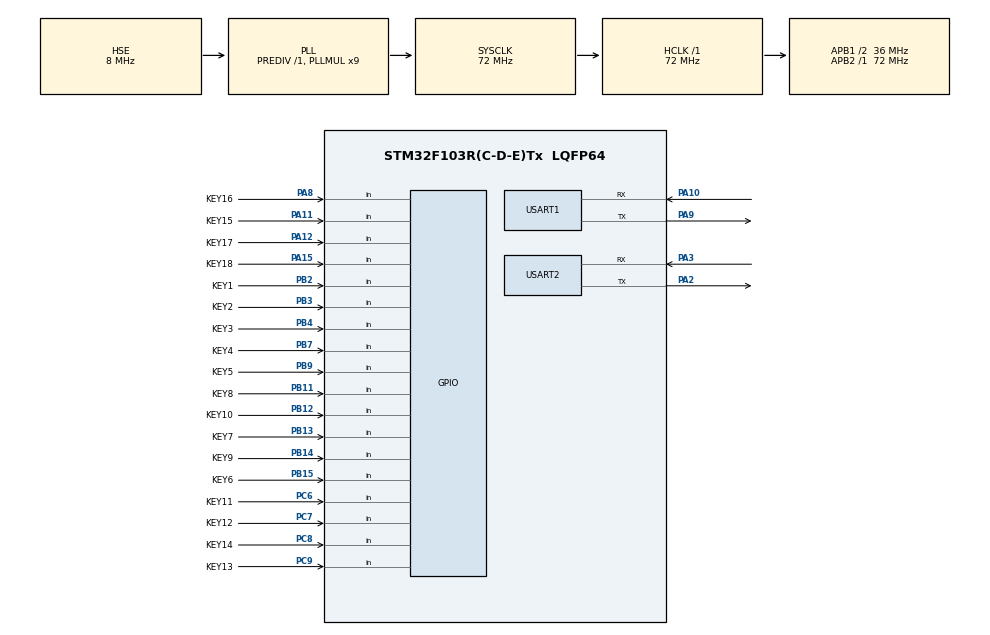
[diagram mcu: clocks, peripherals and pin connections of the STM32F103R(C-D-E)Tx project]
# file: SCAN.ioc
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Mcu.Family=STM32F1
Mcu.Name=STM32F103R(C-D-E)Tx
Mcu.Package=LQFP64
NVIC.PriorityGroup=NVIC_PRIORITYGROUP_4
NVIC.USART1_IRQn=true\:0\:0\:false\:false\:true
NVIC.USART2_IRQn=true\:0\:0\:false\:false\:true
PA10.Mode=Asynchronous
PA10.Signal=USART1_RX
PA11.GPIO_Label=KEY15
PA11.Signal=GPIO_Input
PA12.GPIO_Label=KEY17
PA12.Signal=GPIO_Input
PA13.Mode=Serial_Wire
PA13.Signal=SYS_JTMS-SWDIO
PA14.Mode=Serial_Wire
PA14.Signal=SYS_JTCK-SWCLK
PA15.GPIO_Label=KEY18
PA15.Signal=GPIO_Input
PA2.Mode=Asynchronous
PA2.Signal=USART2_TX
PA3.Mode=Asynchronous
PA3.Signal=USART2_RX
PA8.GPIO_Label=KEY16
PA8.Signal=GPIO_Input
PA9.Mode=Asynchronous
PA9.Signal=USART1_TX
PB11.GPIO_Label=KEY8
PB11.Signal=GPIO_Input
PB12.GPIO_Label=KEY10
PB12.Signal=GPIO_Input
PB13.GPIO_Label=KEY7
PB13.Signal=GPIO_Input
PB14.GPIO_Label=KEY9
PB14.Signal=GPIO_Input
PB15.GPIO_Label=KEY6
PB15.Signal=GPIO_Input
PB2.GPIO_Label=KEY1
PB2.Signal=GPIO_Input
PB3.GPIO_Label=KEY2
PB3.Signal=GPIO_Input
PB4.GPIO_Label=KEY3
PB4.Signal=GPIO_Input
PB7.GPIO_Label=KEY4
PB7.Signal=GPIO_Input
PB9.GPIO_Label=KEY5
PB9.Signal=GPIO_Input
PC6.GPIO_Label=KEY11
PC6.Signal=GPIO_Input
PC7.GPIO_Label=KEY12
PC7.Signal=GPIO_Input
PC8.GPIO_Label=KEY14
PC8.Signal=GPIO_Input
PC9.GPIO_Label=KEY13
PC9.Signal=GPIO_Input
PD0-OSC_IN.Mode=HSE-External-Oscillator
PD0-OSC_IN.Signal=RCC_OSC_IN
PD1-OSC_OUT.Mode=HSE-External-Oscillator
PD1-OSC_OUT.Signal=RCC_OSC_OUT
ProjectManager.HeapSize=0x200
ProjectManager.StackSize=0x400
ProjectManager.TargetToolchain=MDK-ARM V5
RCC.AHBFreq_Value=72000000
RCC.APB1CLKDivider=RCC_HCLK_DIV2
RCC.APB1Freq_Value=36000000
RCC.APB1TimFreq_Value=72000000
RCC.APB2Freq_Value=72000000
RCC.APB2TimFreq_Value=72000000
RCC.HCLKFreq_Value=72000000
RCC.HSIState=RCC_HSI_ON
RCC.PLLMUL=RCC_PLL_MUL9
RCC.PLLSourceVirtual=RCC_PLLSOURCE_HSE
RCC.SYSCLKFreq_VALUE=72000000
RCC.SYSCLKSource=RCC_SYSCLKSOURCE_PLLCLK
RCC.USBFreq_Value=72000000
board=SCAN

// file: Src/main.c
/**
  ******************************************************************************
  * File Name          : main.c
  * Description        : Main program body
  ******************************************************************************
  *
  * COPYRIGHT(c) 2016 STMicroelectronics
  *
  * Redistribution and use in source and binary forms, with or without modification,
  * are permitted provided that the following conditions are met:
  *   1. Redistributions of source code must retain the above copyright notice,
  *      this list of conditions and the following disclaimer.
  *   2. Redistributions in binary form must reproduce the above copyright notice,
  *      this list of conditions and the following disclaimer in the documentation
  *      and/or other materials provided with the distribution.
  *   3. Neither the name of STMicroelectronics nor the names of its contributors
  *      may be used to endorse or promote products derived from this software
  *      without specific prior written permission.
  *
  * THIS SOFTWARE IS PROVIDED BY THE COPYRIGHT HOLDERS AND CONTRIBUTORS "AS IS"
  * AND ANY EXPRESS OR IMPLIED WARRANTIES, INCLUDING, BUT NOT LIMITED TO, THE
  * IMPLIED WARRANTIES OF MERCHANTABILITY AND FITNESS FOR A PARTICULAR PURPOSE ARE
  * DISCLAIMED. IN NO EVENT SHALL THE COPYRIGHT HOLDER OR CONTRIBUTORS BE LIABLE
  * FOR ANY DIRECT, INDIRECT, INCIDENTAL, SPECIAL, EXEMPLARY, OR CONSEQUENTIAL
  * DAMAGES (INCLUDING, BUT NOT LIMITED TO, PROCUREMENT OF SUBSTITUTE GOODS OR
  * SERVICES; LOSS OF USE, DATA, OR PROFITS; OR BUSINESS INTERRUPTION) HOWEVER
  * CAUSED AND ON ANY THEORY OF LIABILITY, WHETHER IN CONTRACT, STRICT LIABILITY,
  * OR TORT (INCLUDING NEGLIGENCE OR OTHERWISE) ARISING IN ANY WAY OUT OF THE USE
  * OF THIS SOFTWARE, EVEN IF ADVISED OF THE POSSIBILITY OF SUCH DAMAGE.
  *
  ******************************************************************************
  */
#include "stm32f1xx_hal.h"

/* USER CODE BEGIN Includes */
#include "key.h"
#include "BlueTooth.h"
/* USER CODE END Includes */

UART_HandleTypeDef huart1;
UART_HandleTypeDef huart2;

/* USER CODE BEGIN PV */
/* Private variables ---------------------------------------------------------*/
uint8_t usart1_temp = 0;
uint8_t HandshakeSignalFirst[4] = {0xEE,  0xf0, 0x0d, 0x0a};
uint8_t HandshakeSignalSecond = 0x01;
uint8_t HandshakeSignalThird[4] = {0xEE,  0x0f, 0x0d, 0x0a}; //与扫描单片机握手信号

/* USER CODE END PV */

void SystemClock_Config(void);
void Error_Handler(void);
static void MX_GPIO_Init(void);
static void MX_USART1_UART_Init(void);
static void MX_USART2_UART_Init(void);

/* USER CODE BEGIN PFP */
/* Private function prototypes -----------------------------------------------*/

/* USER CODE END PFP */

int main(void)
{

    /* MCU Configuration----------------------------------------------------------*/

    /* Reset of all peripherals, Initializes the Flash interface and the Systick. */
    HAL_Init();

    /* Configure the system clock */
    SystemClock_Config();

    /* Initialize all configured peripherals */
    MX_GPIO_Init();
    MX_USART1_UART_Init();
    MX_USART2_UART_Init();

    /* USER CODE BEGIN 2 */
    while (HAL_UART_Receive_IT(&huart1, &usart1_temp,
                               sizeof(usart1_temp)) != HAL_OK);//开启串口中断
    /*握手协议
    扫描单片机发送HandshakeSignalFirst至小车，
      小车接收到这个信号则发送HandshakeSignalSecond至扫描单片机
    扫描单片机发送HandshakeSignalThird至小车，小车收到就开始下一步
    */
    while (usart1_temp != HandshakeSignalSecond)
    {
        HAL_UART_Transmit(&huart1 , HandshakeSignalFirst, 4, 0xff);
        HAL_Delay(5);
    }
    HAL_UART_Transmit(&huart1 , HandshakeSignalThird, 4, 0xff);

    /* USER CODE END 2 */

    /* Infinite loop */
    while (1)
    {

        /* USER CODE BEGIN 3 */
        SendData();
        HAL_Delay(10);

    }
    /* USER CODE END 3 */

}

/** System Clock Configuration
*/
void SystemClock_Config(void)
{

    RCC_OscInitTypeDef RCC_OscInitStruct;
    RCC_ClkInitTypeDef RCC_ClkInitStruct;

    RCC_OscInitStruct.OscillatorType = RCC_OSCILLATORTYPE_HSE;
    RCC_OscInitStruct.HSEState = RCC_HSE_ON;
    RCC_OscInitStruct.HSEPredivValue = RCC_HSE_PREDIV_DIV1;
    RCC_OscInitStruct.PLL.PLLState = RCC_PLL_ON;
    RCC_OscInitStruct.PLL.PLLSource = RCC_PLLSOURCE_HSE;
    RCC_OscInitStruct.PLL.PLLMUL = RCC_PLL_MUL9;
    if (HAL_RCC_OscConfig(&RCC_OscInitStruct) != HAL_OK)
    {
        Error_Handler();
    }

    RCC_ClkInitStruct.ClockType = RCC_CLOCKTYPE_HCLK | RCC_CLOCKTYPE_SYSCLK
                                  | RCC_CLOCKTYPE_PCLK1 | RCC_CLOCKTYPE_PCLK2;
    RCC_ClkInitStruct.SYSCLKSource = RCC_SYSCLKSOURCE_PLLCLK;
    RCC_ClkInitStruct.AHBCLKDivider = RCC_SYSCLK_DIV1;
    RCC_ClkInitStruct.APB1CLKDivider = RCC_HCLK_DIV2;
    RCC_ClkInitStruct.APB2CLKDivider = RCC_HCLK_DIV1;
    if (HAL_RCC_ClockConfig(&RCC_ClkInitStruct, FLASH_LATENCY_2) != HAL_OK)
    {
        Error_Handler();
    }

    HAL_SYSTICK_Config(HAL_RCC_GetHCLKFreq() / 1000);

    HAL_SYSTICK_CLKSourceConfig(SYSTICK_CLKSOURCE_HCLK);

    /* SysTick_IRQn interrupt configuration */
    HAL_NVIC_SetPriority(SysTick_IRQn, 0, 0);
}

/* USART1 init function */
static void MX_USART1_UART_Init(void)
{

    huart1.Instance = USART1;
    huart1.Init.BaudRate = 115200;
    huart1.Init.WordLength = UART_WORDLENGTH_8B;
    huart1.Init.StopBits = UART_STOPBITS_1;
    huart1.Init.Parity = UART_PARITY_NONE;
    huart1.Init.Mode = UART_MODE_TX_RX;
    huart1.Init.HwFlowCtl = UART_HWCONTROL_NONE;
    huart1.Init.OverSampling = UART_OVERSAMPLING_16;
    if (HAL_UART_Init(&huart1) != HAL_OK)
    {
        Error_Handler();
    }

}

/* USART2 init function */
static void MX_USART2_UART_Init(void)
{

    huart2.Instance = USART2;
    huart2.Init.BaudRate = 115200;
    huart2.Init.WordLength = UART_WORDLENGTH_8B;
    huart2.Init.StopBits = UART_STOPBITS_1;
    huart2.Init.Parity = UART_PARITY_NONE;
    huart2.Init.Mode = UART_MODE_TX_RX;
    huart2.Init.HwFlowCtl = UART_HWCONTROL_NONE;
    huart2.Init.OverSampling = UART_OVERSAMPLING_16;
    if (HAL_UART_Init(&huart2) != HAL_OK)
    {
        Error_Handler();
    }

}

/** Configure pins as
        * Analog
        * Input
        * Output
        * EVENT_OUT
        * EXTI
*/
static void MX_GPIO_Init(void)
{

    GPIO_InitTypeDef GPIO_InitStruct;

    /* GPIO Ports Clock Enable */
    __HAL_RCC_GPIOD_CLK_ENABLE();
    __HAL_RCC_GPIOA_CLK_ENABLE();
    __HAL_RCC_GPIOB_CLK_ENABLE();
    __HAL_RCC_GPIOC_CLK_ENABLE();

    /*Configure GPIO pins : KEY1_Pin KEY8_Pin KEY10_Pin KEY7_Pin
                             KEY9_Pin KEY6_Pin KEY2_Pin KEY3_Pin
                             KEY4_Pin KEY5_Pin */
    GPIO_InitStruct.Pin = KEY1_Pin | KEY8_Pin | KEY10_Pin | KEY7_Pin
                          | KEY9_Pin | KEY6_Pin | KEY2_Pin | KEY3_Pin
                          | KEY4_Pin | KEY5_Pin;
    GPIO_InitStruct.Mode = GPIO_MODE_INPUT;
    GPIO_InitStruct.Pull = GPIO_NOPULL;
    HAL_GPIO_Init(GPIOB, &GPIO_InitStruct);

    /*Configure GPIO pins : KEY11_Pin KEY12_Pin KEY14_Pin KEY13_Pin */
    GPIO_InitStruct.Pin = KEY11_Pin | KEY12_Pin | KEY14_Pin | KEY13_Pin;
    GPIO_InitStruct.Mode = GPIO_MODE_INPUT;
    GPIO_InitStruct.Pull = GPIO_NOPULL;
    HAL_GPIO_Init(GPIOC, &GPIO_InitStruct);

    /*Configure GPIO pins : KEY16_Pin KEY15_Pin KEY17_Pin KEY18_Pin */
    GPIO_InitStruct.Pin = KEY16_Pin | KEY15_Pin | KEY17_Pin | KEY18_Pin;
    GPIO_InitStruct.Mode = GPIO_MODE_INPUT;
    GPIO_InitStruct.Pull = GPIO_NOPULL;
    HAL_GPIO_Init(GPIOA, &GPIO_InitStruct);

}

void Error_Handler(void)
{
    while (1)
    {
    }
}

/************************ (C) COPYRIGHT STMicroelectronics *****END OF FILE****/
